AUTOSAR XML (schema 00048)
standard types defined: boolean, sint16, uint8
package /VehicleProject
  system System
package /Diagnostics
  diagnostic contribution set DiagnosticContributionSet: ecu-instance=MyECU, service-tables=DS_MyECU
  diagnostic service table DS_MyECU: diagnostic-connections=DC_0xE001_oMyECU_oCAN00, ecu-instance=MyECU
  diagnostic connection DC_0xE001_oMyECU_oCAN00: physical-request=msg_diag_Request_MyECU_oTN_0x0001_MyECU, response=msg_diag_Response_MyECU_oTN_0x0001_MyECU
package /NM
  nm config NmConfig: can-nm-cluster-coupling=coupled-cluster=CAN00_CAN
    can nm cluster CAN00_CAN: communication-cluster=CAN00, nm-channel-id=0, nm-cbv-position=1, nm-msg-cycle-time=0.1, nm-network-timeout=1, nm-nid-position=0, nm-repeat-message-time=0.4, nm-wait-bus-sleep-time=0.75
      can nm node MyECU: controller=CT_CAN00, nm-if-ecu=MyECU_CAN, nm-node-id=0, rx-nm-pdu=msg_nm_RearECU_oCAN00, tx-nm-pdu=msg_nm_MyECU_oCAN00, nm-msg-cycle-offset=0, nm-msg-reduced-time=0.05, nm-range-config={lower-can-id=1536, upper-can-id=1791}
      can nm node RearECU: nm-if-ecu=RearECU_CAN, nm-node-id=1, rx-nm-pdu=msg_nm_MyECU_oCAN00, tx-nm-pdu=msg_nm_RearECU_oCAN00, nm-msg-cycle-offset=0, nm-msg-reduced-time=0.05, nm-range-config={lower-can-id=1536, upper-can-id=1791}
    nm-if-ecus:
      nm ecu MyECU_CAN: ecu-instance=MyECU, nm-node-id-enabled=true, nm-user-data-enabled=true
      nm ecu RearECU_CAN: nm-node-id-enabled=true, nm-user-data-enabled=true
package /TP
  can tp config CAN00_CAN: communication-cluster=CAN00, can-tp-ecu{cycle-time-main-function=0.005, ecu-instance=MyECU}
    can tp address TA_0x0001: tp-address=1
    can tp address TA_0x00E0: tp-address=224
    can tp channel TPCH: channel-id=0, channel-mode=FULL-DUPLEX-MODE
    can-tp-connection addressing-format=STANDARD, can-tp-channel=TPCH, data-pdu=msg_diag_Request_MyECU_Tp_oCAN00, flow-control-pdu=msg_diag_Response_MyECU_Tp_oCAN00, receiver=TN_0x0001_MyECU, ta-type=PHYSICAL, tp-sdu=msg_diag_Request_MyECU_oCAN00, transmitter=TN_0x00E0_Tester:
      ident msg_diag_Request_MyECU_oTN_0x0001_MyECU
    can-tp-connection addressing-format=STANDARD, can-tp-channel=TPCH, data-pdu=msg_diag_RequestGlobal_Tp_oCAN00, flow-control-pdu=msg_diag_Response_MyECU_Tp_oCAN00, receiver=TN_0x0001_MyECU, ta-type=PHYSICAL, tp-sdu=msg_diag_RequestGlobal_oCAN00, transmitter=TN_0x00E0_Tester:
      ident msg_diag_RequestGlobal_oTN_0x0001_MyECU
    can-tp-connection addressing-format=STANDARD, can-tp-channel=TPCH, data-pdu=msg_diag_Response_MyECU_Tp_oCAN00, flow-control-pdu=msg_diag_Request_MyECU_Tp_oCAN00, receiver=TN_0x00E0_Tester, ta-type=PHYSICAL, tp-sdu=msg_diag_Response_MyECU_oCAN00, transmitter=TN_0x0001_MyECU:
      ident msg_diag_Response_MyECU_oTN_0x0001_MyECU
    can tp node TN_0x0001_MyECU: connector=CN_CAN00, tp-address=TA_0x0001
    can tp node TN_0x00E0_Tester: tp-address=TA_0x00E0
package /Cluster
  can cluster CAN00: baudrate=500000, protocol-name=CAN, can-fd-baudrate=500000  # CANFD364 | AUTOSAR series communication matrix (application + CanNm ASR 0x600-0x6FF + UDS diag 0x74C/0x75C/0x7DF). Calibration/XCP is NOT part of this matrix; see CANFD364_XCP_Dev.dbc and configure Xcp PDU in DaVinci/EcuC only.
    can physical channel CHNL: comm-connectors=CN_CAN00
      frame msg_diag_Request_MyECU_oCAN00: id 0x74C, to MyECU, frame-length=8, can-addressing-mode=STANDARD, can-frame-rx-behavior=CAN-20, can-frame-tx-behavior=CAN-20  # UDS physical request (ID 0x74C, Tester -> MyECU), 8 bytes classic CAN. Dcm Rx PDU (physical addressing).
        n pdu msg_diag_Request_MyECU_Tp_oCAN00: length=8
      frame msg_diag_RequestGlobal_oCAN00: id 0x7DF, to MyECU, frame-length=8, can-addressing-mode=STANDARD, can-frame-rx-behavior=CAN-20, can-frame-tx-behavior=CAN-20  # UDS functional request (ID 0x7DF, broadcast), 8 bytes classic CAN. Dcm Rx PDU (functional addressing).
        n pdu msg_diag_RequestGlobal_Tp_oCAN00: length=8
      frame msg_diag_Response_MyECU_oCAN00: id 0x75C, from MyECU, frame-length=8, can-addressing-mode=STANDARD, can-frame-rx-behavior=CAN-20, can-frame-tx-behavior=CAN-20  # UDS physical response (ID 0x75C, MyECU -> Tester), 8 bytes classic CAN. Dcm Tx PDU.
        n pdu msg_diag_Response_MyECU_Tp_oCAN00: length=8
      frame msg_MotorStatus_oCAN00: id 0x511, from MyECU, frame-length=12, can-addressing-mode=STANDARD, can-frame-rx-behavior=ANY, can-frame-tx-behavior=CAN-FD  # MyECU TX motor status (Com). Cycle 5 ms, CAN FD. Signals align with RTE: MotorMode, tle9180_Ov_Fault, Id_Ref, Iq_Ref, Vbus, ElectricAngle. Observation only; mode/current commands via XCP RAM write, not Com Rx.
        pdu msg_MotorStatus_oCAN00: length=12, minimum-delay=0, transmission-mode-false-timing=cyclic-timing={time-offset=0, time-period=0.005}, transmission-mode-true-timing=cyclic-timing={time-offset=0, time-period=0.005}, unused-bit-pattern=0
          signal MotorMode_omsg_MotorStatus_oCAN00: start 0, 8 bit, little-endian, i-signal-type=PRIMITIVE, init-value=0, base-type=uint8, compu {0=Cx00_Idle, 1=Cx01_Stop, 2=Cx02_FocSpeed, 3=Cx03_FocCurrent, 4=Cx04_OpenLoop, 5=Cx05_Calibration, 6=Cx06_CalibrationErase, 7=Cx07_CalibrationSave}, range raw 0..7, transfer-property=PENDING  # Aligned with MotorMode_Type in MotorMode.h (0..7).
          signal tle9180_Ov_Fault_omsg_MotorStatus_oCAN00: start 8, 1 bit, little-endian, i-signal-type=PRIMITIVE, init-value=0, base-type=boolean, compu {0=Cx0_NoFault, 1=Cx1_OverVoltageFault}, range raw 0..1, transfer-property=PENDING
          signal Id_Ref_omsg_MotorStatus_oCAN00: start 16, 16 bit, little-endian, i-signal-type=PRIMITIVE, init-value=0, base-type=sint16, compu {phys=raw*0.01 for raw -32768..32767; unit A}, range raw -32768..32767, unit=A, transfer-property=PENDING  # Actual Id current reference after clamp [A].
          signal Iq_Ref_omsg_MotorStatus_oCAN00: start 32, 16 bit, little-endian, i-signal-type=PRIMITIVE, init-value=0, base-type=sint16, compu {phys=raw*0.01 for raw -32768..32767; unit A}, range raw -32768..32767, unit=A, transfer-property=PENDING  # Actual Iq current reference after clamp [A].
          signal Vbus_omsg_MotorStatus_oCAN00: start 48, 16 bit, little-endian, i-signal-type=PRIMITIVE, init-value=0, base-type=sint16, compu {phys=raw*0.1 for raw -32768..32767; unit V}, range raw -32768..32767, unit=V, transfer-property=PENDING
          signal ElectricAngle_omsg_MotorStatus_oCAN00: start 64, 16 bit, little-endian, i-signal-type=PRIMITIVE, init-value=0, base-type=sint16, compu {phys=raw*0.001 for raw -32768..32767; unit rad}, range raw -32768..32767, unit=rad, transfer-property=PENDING
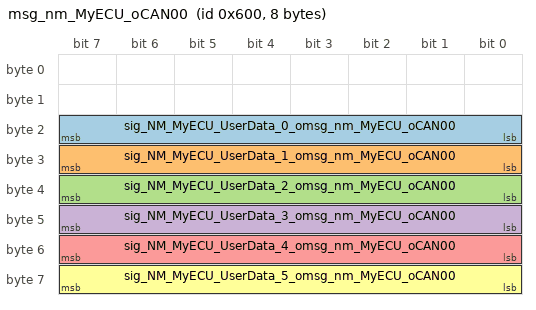
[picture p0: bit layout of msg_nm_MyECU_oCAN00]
      frame msg_nm_MyECU_oCAN00: id 0x600, from MyECU, frame-length=8, can-addressing-mode=STANDARD, can-frame-rx-behavior=ANY, can-frame-tx-behavior=CAN-20  # CanNm ASR TX MyECU ID=0x600. Layout 8B: [SNI/NID][CBV][UserData0..5]. CanNm fills SNI+CBV; Com UserDataTxPdu length must be 6.
        nm pdu msg_nm_MyECU_oCAN00: length=8, unused-bit-pattern=0
          signal sig_NM_MyECU_UserData_0_omsg_nm_MyECU_oCAN00: start 16, 8 bit, little-endian, i-signal-type=PRIMITIVE, init-value=0, base-type=uint8, compu {identical}, range raw 0..255, transfer-property=PENDING  # User data byte0 (frame byte2). Part of Com UserDataTxPdu (6 bytes).
          signal sig_NM_MyECU_UserData_1_omsg_nm_MyECU_oCAN00: start 24, 8 bit, little-endian, i-signal-type=PRIMITIVE, init-value=0, base-type=uint8, compu {identical}, range raw 0..255, transfer-property=PENDING
          signal sig_NM_MyECU_UserData_2_omsg_nm_MyECU_oCAN00: start 32, 8 bit, little-endian, i-signal-type=PRIMITIVE, init-value=0, base-type=uint8, compu {identical}, range raw 0..255, transfer-property=PENDING
          signal sig_NM_MyECU_UserData_3_omsg_nm_MyECU_oCAN00: start 40, 8 bit, little-endian, i-signal-type=PRIMITIVE, init-value=0, base-type=uint8, compu {identical}, range raw 0..255, transfer-property=PENDING
          signal sig_NM_MyECU_UserData_4_omsg_nm_MyECU_oCAN00: start 48, 8 bit, little-endian, i-signal-type=PRIMITIVE, init-value=0, base-type=uint8, compu {identical}, range raw 0..255, transfer-property=PENDING
          signal sig_NM_MyECU_UserData_5_omsg_nm_MyECU_oCAN00: start 56, 8 bit, little-endian, i-signal-type=PRIMITIVE, init-value=0, base-type=uint8, compu {identical}, range raw 0..255, transfer-property=PENDING
      frame msg_nm_RearECU_oCAN00: id 0x601, to MyECU, frame-length=8, can-addressing-mode=STANDARD, can-frame-rx-behavior=ANY, can-frame-tx-behavior=CAN-20  # CanNm ASR TX RearECU ID=0x601. Same 8B layout. MyECU RX via CanNm range 0x600-0x6FF.
        nm pdu msg_nm_RearECU_oCAN00: length=8, unused-bit-pattern=0
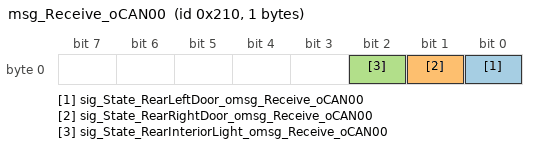
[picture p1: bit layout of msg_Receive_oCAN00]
      frame msg_Receive_oCAN00: id 0x210, to MyECU, frame-length=1, can-addressing-mode=STANDARD, can-frame-rx-behavior=ANY, can-frame-tx-behavior=CAN-20  # Legacy demo RX frame (kept for existing CanIf/Com). Prefer remove in later series cleanup if unused.
        pdu msg_Receive_oCAN00: length=1, minimum-delay=0, transmission-mode-false-timing=cyclic-timing={time-offset=0, time-period=0.1}, transmission-mode-true-timing=cyclic-timing={time-offset=0, time-period=0.1}, unused-bit-pattern=0
          signal sig_State_RearLeftDoor_omsg_Receive_oCAN00: start 0, 1 bit, little-endian, i-signal-type=PRIMITIVE, init-value=0, base-type=boolean, compu {identical}, range raw 0..1, transfer-property=PENDING, to MyECU
          signal sig_State_RearRightDoor_omsg_Receive_oCAN00: start 1, 1 bit, little-endian, i-signal-type=PRIMITIVE, init-value=0, base-type=boolean, compu {identical}, range raw 0..1, transfer-property=PENDING, to MyECU
          signal sig_State_RearInteriorLight_omsg_Receive_oCAN00: start 2, 1 bit, little-endian, i-signal-type=PRIMITIVE, init-value=0, base-type=boolean, compu {identical}, range raw 0..1, transfer-property=PENDING, to MyECU
      frame msg_Transmit_oCAN00: id 0x200, from MyECU, frame-length=1, can-addressing-mode=STANDARD, can-frame-rx-behavior=ANY, can-frame-tx-behavior=CAN-20  # Legacy demo TX frame (kept for existing CanIf/Com). Prefer remove in later series cleanup if unused.
        pdu msg_Transmit_oCAN00: length=1, minimum-delay=0, transmission-mode-false-timing=cyclic-timing={time-offset=0, time-period=0.1}, transmission-mode-true-timing=cyclic-timing={time-offset=0, time-period=0.1}, unused-bit-pattern=0
          signal sig_RearInteriorLight_omsg_Transmit_oCAN00: start 0, 1 bit, little-endian, i-signal-type=PRIMITIVE, init-value=0, base-type=boolean, compu {identical}, range raw 0..1, transfer-property=PENDING
      pdu triggering PT_msg_diag_Request_MyECU: pdu=msg_diag_Request_MyECU_oCAN00, to MyECU
      pdu triggering PT_msg_diag_RequestGlobal: pdu=msg_diag_RequestGlobal_oCAN00, to MyECU
      pdu triggering PT_msg_diag_Response_MyECU: pdu=msg_diag_Response_MyECU_oCAN00, from MyECU
package /ECU
  ecu instance MyECU: associated-com-i-pdu-group=[MyECU_oCAN00_Rx, MyECU_oCAN00_Tx]
    can communication controller CT_CAN00
    can communication connector CN_CAN00: comm-controller=CT_CAN00
package /IPDUGroup
  i signal i pdu group MyECU_oCAN00_Rx: communication-direction=IN, i-signal-i-pdus=msg_Receive_oCAN00
  i signal i pdu group MyECU_oCAN00_Tx: communication-direction=OUT, i-signal-i-pdus=[msg_MotorStatus_oCAN00, msg_Transmit_oCAN00]
package /PDU
  dcm i pdu msg_diag_Request_MyECU_oCAN00: length=8, diag-pdu-type=DIAG-REQUEST
  dcm i pdu msg_diag_RequestGlobal_oCAN00: length=8, diag-pdu-type=DIAG-REQUEST
  dcm i pdu msg_diag_Response_MyECU_oCAN00: length=8, diag-pdu-type=DIAG-RESPONSE
package /DataType/Unit
  unit U_A: display-name=A
  unit U_rad: display-name=rad
  unit U_V: display-name=V
